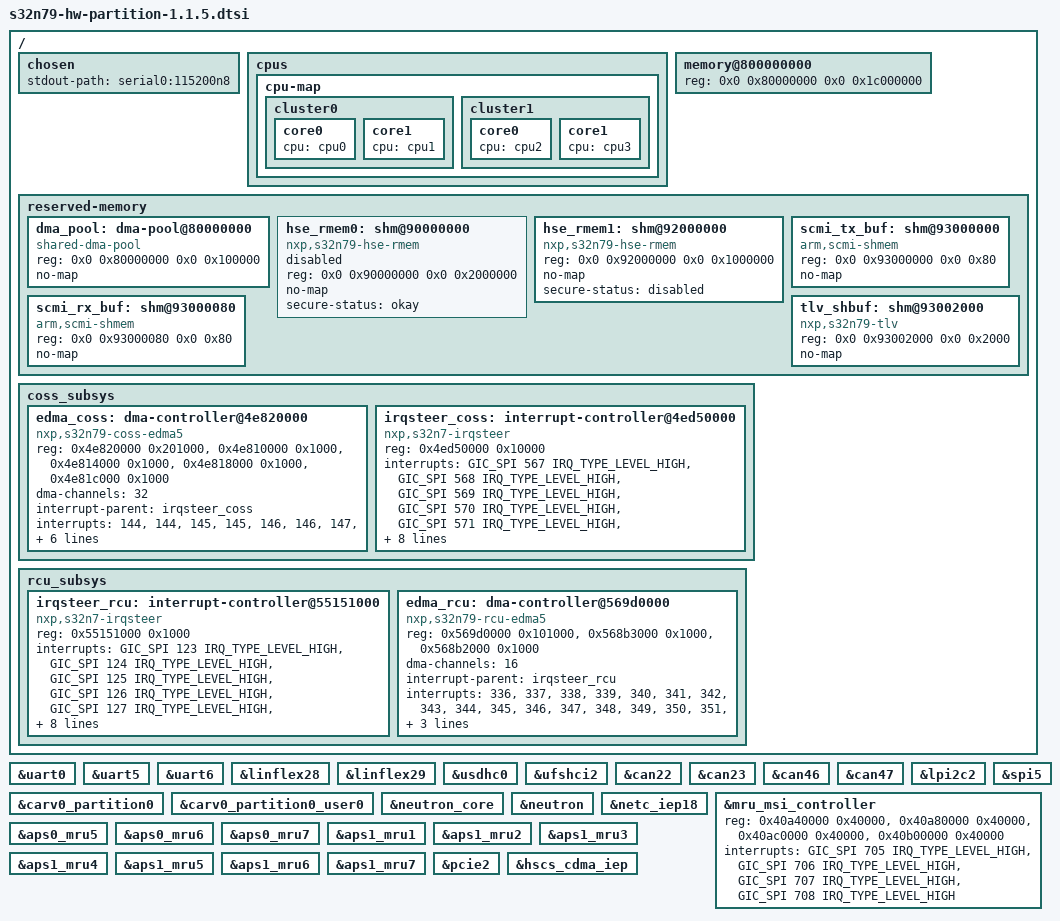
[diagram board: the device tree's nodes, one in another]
// SPDX-License-Identifier: (GPL-2.0+ OR BSD-3-Clause)
/*
 * Copyright 2024-2026 NXP
 */

/delete-node/ &cpu4;
/delete-node/ &cpu5;
/delete-node/ &cpu6;
/delete-node/ &cpu7;
/delete-node/ &irqsteer_coss;
/delete-node/ &irqsteer_rcu;
/delete-node/ &edma_coss;
/delete-node/ &edma_rcu;
/delete-node/ &netc_iep14;
/delete-node/ &netc_iep19;
/delete-node/ &ufshc;
/delete-node/ &ufshci0;
/delete-node/ &ufshci1;
/delete-node/ &ufshci3;
/delete-node/ &dma_pool;
/delete-node/ &carv0_partition0_user1;
/delete-node/ &carv0_partition0_user2;
/delete-node/ &carv0_partition0_user3;

/ {
	chosen {
		stdout-path = "serial0:115200n8";
	};

	cpus {
		cpu-map {
			cluster0 {
				core0 {
					cpu = <&cpu0>;
				};

				core1 {
					cpu = <&cpu1>;
				};
			};

			cluster1 {
				core0 {
					cpu = <&cpu2>;
				};

				core1 {
					cpu = <&cpu3>;
				};
			};
		};
	};

	memory@800000000 {
		device_type = "memory";
		reg = <0x0 0x80000000 0x0 0x1c000000>;
	};

	reserved-memory {
		#address-cells = <2>;
		#size-cells = <2>;
		ranges;

		dma_pool: dma-pool@80000000 {
			compatible = "shared-dma-pool";
			reg = <0x0 0x80000000 0x0 0x100000>; /* 1 MB */
			no-map;
		};

		hse_rmem0: shm@90000000 {
			compatible = "nxp,s32n79-hse-rmem";
			reg = <0x0 0x90000000 0x0 0x2000000>; /* 32 MB */
			no-map;
			status = "disabled";
			secure-status = "okay";
		};

		hse_rmem1: shm@92000000 {
			compatible = "nxp,s32n79-hse-rmem";
			reg = <0x0 0x92000000 0x0 0x1000000>; /* 16 MB */
			no-map;
			status = "okay";
			secure-status = "disabled";
		};

		scmi_tx_buf: shm@93000000 {
			compatible = "arm,scmi-shmem";
			reg = <0x0 0x93000000 0x0 0x80>;
			no-map;
		};

		scmi_rx_buf: shm@93000080 {
			compatible = "arm,scmi-shmem";
			reg = <0x0 0x93000080 0x0 0x80>;
			no-map;
		};

		tlv_shbuf: shm@93002000 {
			compatible = "nxp,s32n79-tlv";
			reg = <0x0 0x93002000 0x0 0x2000>;
			no-map;
		};
	};

	coss_subsys {
		edma_coss: dma-controller@4e820000 {
			compatible = "nxp,s32n79-coss-edma5";
			reg = <0x4e820000 0x201000>,
			      <0x4e810000 0x1000>,
			      <0x4e814000 0x1000>,
			      <0x4e818000 0x1000>,
			      <0x4e81c000 0x1000>;
			#dma-cells = <2>;
			dma-channels = <32>;
			interrupt-parent = <&irqsteer_coss>;
			/* Two DMA channels share the same interrupt. */
			interrupts = <144>, <144>, <145>, <145>,
				     <146>, <146>, <147>, <147>,
				     <148>, <148>, <149>, <149>,
				     <150>, <150>, <151>, <151>,
				     <252>, <252>, <253>, <253>,
				     <254>, <254>, <255>, <255>,
				     <256>, <256>, <257>, <257>,
				     <258>, <258>, <259>, <259>,
				     <453>;
			clocks = <&clks 0x90>, <&clks 0x9a>,
				<&clks 0x90>, <&clks 0x9a>;
			clock-names = "dmamux0", "dmamux1", "dmamux2", "dmamux3";
			dma-coherent;
		};

		irqsteer_coss: interrupt-controller@4ed50000 {
			compatible = "nxp,s32n7-irqsteer";
			reg = <0x4ed50000 0x10000>;
			interrupts = <GIC_SPI 567 IRQ_TYPE_LEVEL_HIGH>,
				     <GIC_SPI 568 IRQ_TYPE_LEVEL_HIGH>,
				     <GIC_SPI 569 IRQ_TYPE_LEVEL_HIGH>,
				     <GIC_SPI 570 IRQ_TYPE_LEVEL_HIGH>,
				     <GIC_SPI 571 IRQ_TYPE_LEVEL_HIGH>,
				     <GIC_SPI 572 IRQ_TYPE_LEVEL_HIGH>,
				     <GIC_SPI 573 IRQ_TYPE_LEVEL_HIGH>,
				     <GIC_SPI 574 IRQ_TYPE_LEVEL_HIGH>;
			interrupt-controller;
			interrupt-parent = <&gic>;
			#interrupt-cells = <1>;
			clocks = <&clks 0x9a>;
			clock-names = "ipg";
			fsl,channel = <0>;
			fsl,num-irqs = <512>;
		};
	};

	rcu_subsys {
		irqsteer_rcu: interrupt-controller@55151000 {
			compatible = "nxp,s32n7-irqsteer";
			reg = <0x55151000 0x1000>;
			interrupts = <GIC_SPI 123 IRQ_TYPE_LEVEL_HIGH>,
				     <GIC_SPI 124 IRQ_TYPE_LEVEL_HIGH>,
				     <GIC_SPI 125 IRQ_TYPE_LEVEL_HIGH>,
				     <GIC_SPI 126 IRQ_TYPE_LEVEL_HIGH>,
				     <GIC_SPI 127 IRQ_TYPE_LEVEL_HIGH>,
				     <GIC_SPI 128 IRQ_TYPE_LEVEL_HIGH>,
				     <GIC_SPI 129 IRQ_TYPE_LEVEL_HIGH>,
				     <GIC_SPI 130 IRQ_TYPE_LEVEL_HIGH>;
			interrupt-controller;
			interrupt-parent = <&gic>;
			#interrupt-cells = <1>;
			clocks = <&clks 0xf9>;
			clock-names = "ipg";
			fsl,channel = <0>;
			fsl,num-irqs = <512>;
		};

		edma_rcu: dma-controller@569d0000 {
			compatible = "nxp,s32n79-rcu-edma5";
			reg = <0x569d0000 0x101000>,
				<0x568b3000 0x1000>,
				<0x568b2000 0x1000>;
			#dma-cells = <2>;
			dma-channels = <16>;
			interrupt-parent = <&irqsteer_rcu>;
			interrupts = <336>, <337>, <338>, <339>,
				     <340>, <341>, <342>, <343>,
				     <344>, <345>, <346>, <347>,
				     <348>, <349>, <350>, <351>,
				     <393>;
			clocks = <&clks 0xf8>, <&clks 0xf9>;
			clock-names = "dmamux0", "dmamux1";
			memory-region = <&dma_pool>;
		};
	};
};

&uart0 {
	status = "okay";
};

&uart5 {
	status = "okay";
};

&uart6 {
	status = "okay";
};

&linflex28 {
	status = "okay";
};

&linflex29 {
	status = "okay";
};

&usdhc0 {
	status = "okay";
};

&ufshci2 {
	status = "okay";
};

&can22 {
	status = "okay";
};

&can23 {
	status = "okay";
};

&can46 {
	status = "okay";
};

&can47 {
	status = "okay";
};

&lpi2c2 {
	status = "okay";
};

&spi5 {
	status = "okay";
};

&carv0_partition0 {
	status = "okay";
};

&carv0_partition0_user0 {
	status = "okay";
};

&neutron_core {
	status = "okay";
};

&neutron {
	status = "okay";
};

&netc_iep18 {
	status = "okay";
};

&mru_msi_controller {
	reg = <0x40a40000 0x40000>,
	      <0x40a80000 0x40000>,
	      <0x40ac0000 0x40000>,
	      <0x40b00000 0x40000>;
	interrupts = <GIC_SPI 705 IRQ_TYPE_LEVEL_HIGH>,
		     <GIC_SPI 706 IRQ_TYPE_LEVEL_HIGH>,
		     <GIC_SPI 707 IRQ_TYPE_LEVEL_HIGH>,
		     <GIC_SPI 708 IRQ_TYPE_LEVEL_HIGH>;
	status = "okay";
};

&aps0_mru5 {
	status = "okay";
};

&aps0_mru6 {
	status = "okay";
};

&aps0_mru7 {
	status = "okay";
};

&aps1_mru1 {
	status = "okay";
};

&aps1_mru2 {
	status = "okay";
};

&aps1_mru3 {
	status = "okay";
};

&aps1_mru4 {
	status = "okay";
};

&aps1_mru5 {
	status = "okay";
};

&aps1_mru6 {
	status = "okay";
};

&aps1_mru7 {
	status = "okay";
};

&pcie2 {
	status = "okay";
};

&hscs_cdma_iep {
	status = "okay";
};
